# ATSAM4LC4C device description
Architecture: CORTEX-M4; Family: SAM4; Series: SAM4L
Registers are 32-bit, read-write, reset 0x0 unless marked. A register's access mark holds for its fields unless they carry their own. Offsets are from the block's base; [hi:lo] are bit positions; lines under a group give offsets from that group; {n}, {i} and the like mark numbered series.

## GPIO — General-Purpose Input/Output Controller
Instances: GPIO 0x400E1000
{0x0+0x200*i} port[{i}] (i=0..2) group
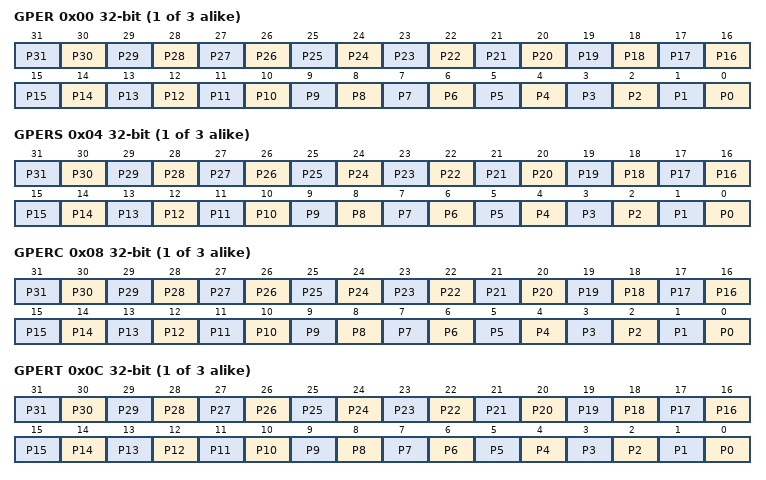
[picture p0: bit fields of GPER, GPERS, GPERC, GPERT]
  0x00 GPER reset not defined — GPIO Enable Register
    [n] P{n} (n=0..31) — GPIO Enable
  0x04 GPERS wo reset not defined (atomic set of GPER) — GPIO Enable Register - Set
    [n] P{n} (n=0..31) — GPIO Enable
  0x08 GPERC wo reset not defined (atomic clear of GPER) — GPIO Enable Register - Clear
    [n] P{n} (n=0..31) — GPIO Enable
  0x0C GPERT wo reset not defined (atomic toggle of GPER) — GPIO Enable Register - Toggle
    [n] P{n} (n=0..31) — GPIO Enable
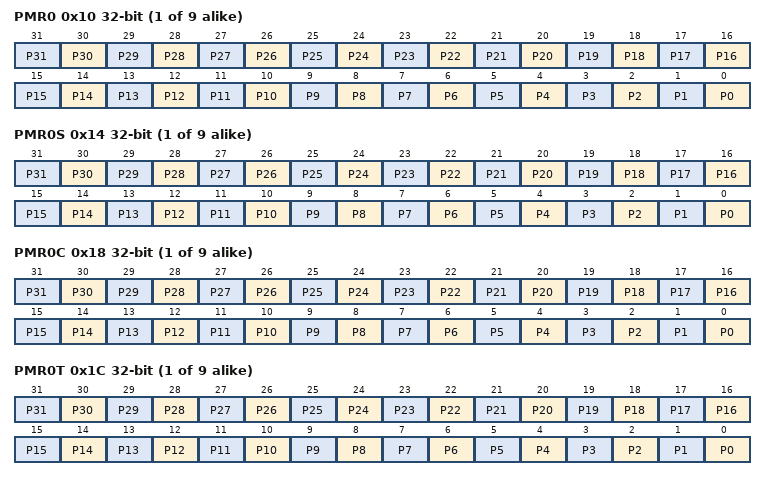
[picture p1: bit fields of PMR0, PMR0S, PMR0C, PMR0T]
  {0x10+0x10*j} PMR{j} reset not defined (j=0..2) — Peripheral Mux Register {j}
    [n] P{n} (n=0..31) — Peripheral Multiplexer Select bit {j}
  {0x14+0x10*j} PMR{j}S wo reset not defined (atomic set of PMR{j}) (j=0..2) — Peripheral Mux Register {j} - Set
    [n] P{n} (n=0..31) — Peripheral Multiplexer Select bit {j}
  {0x18+0x10*j} PMR{j}C wo reset not defined (atomic clear of PMR{j}) (j=0..2) — Peripheral Mux Register {j} - Clear
    [n] P{n} (n=0..31) — Peripheral Multiplexer Select bit {j}
  {0x1C+0x10*j} PMR{j}T wo reset not defined (atomic toggle of PMR{j}) (j=0..2) — Peripheral Mux Register {j} - Toggle
    [n] P{n} (n=0..31) — Peripheral Multiplexer Select bit {j}
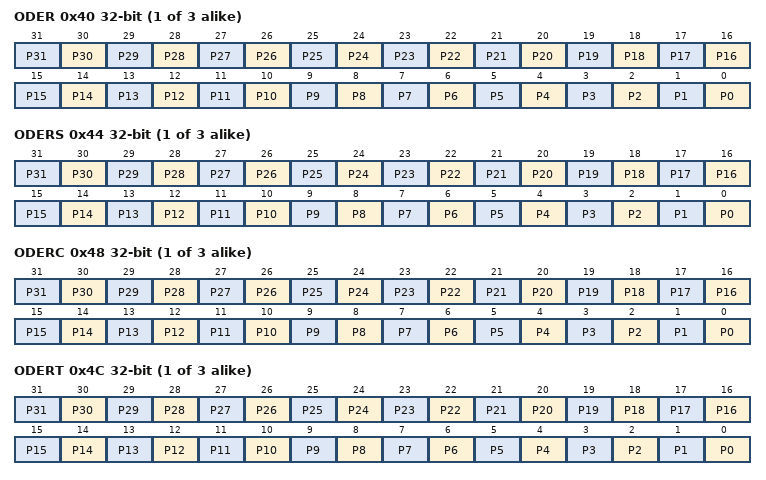
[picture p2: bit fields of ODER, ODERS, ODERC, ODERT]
  0x40 ODER reset not defined — Output Driver Enable Register
    [n] P{n} (n=0..31) — Output Driver Enable
  0x44 ODERS wo reset not defined (atomic set of ODER) — Output Driver Enable Register - Set
    [n] P{n} (n=0..31) — Output Driver Enable
  0x48 ODERC wo reset not defined (atomic clear of ODER) — Output Driver Enable Register - Clear
    [n] P{n} (n=0..31) — Output Driver Enable
  0x4C ODERT wo reset not defined (atomic toggle of ODER) — Output Driver Enable Register - Toggle
    [n] P{n} (n=0..31) — Output Driver Enable
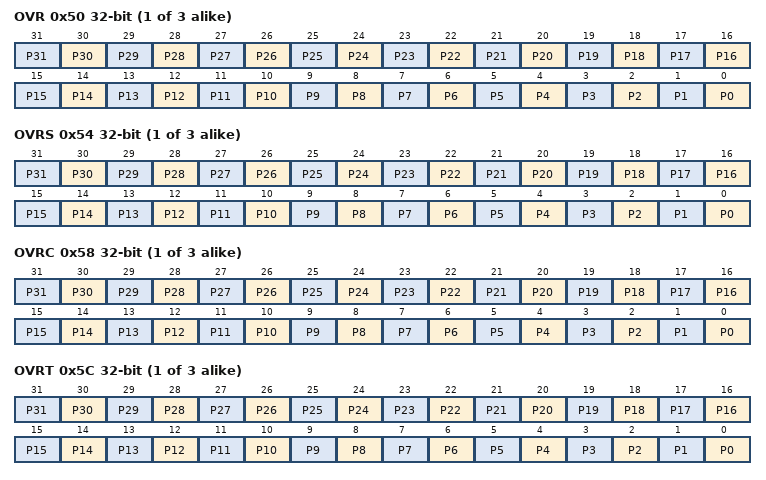
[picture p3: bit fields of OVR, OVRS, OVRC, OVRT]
  0x50 OVR reset not defined — Output Value Register
    [n] P{n} (n=0..31) — Output Value
  0x54 OVRS wo reset not defined (atomic set of OVR) — Output Value Register - Set
    [n] P{n} (n=0..31) — Output Value
  0x58 OVRC wo reset not defined (atomic clear of OVR) — Output Value Register - Clear
    [n] P{n} (n=0..31) — Output Value
  0x5C OVRT wo reset not defined (atomic toggle of OVR) — Output Value Register - Toggle
    [n] P{n} (n=0..31) — Output Value
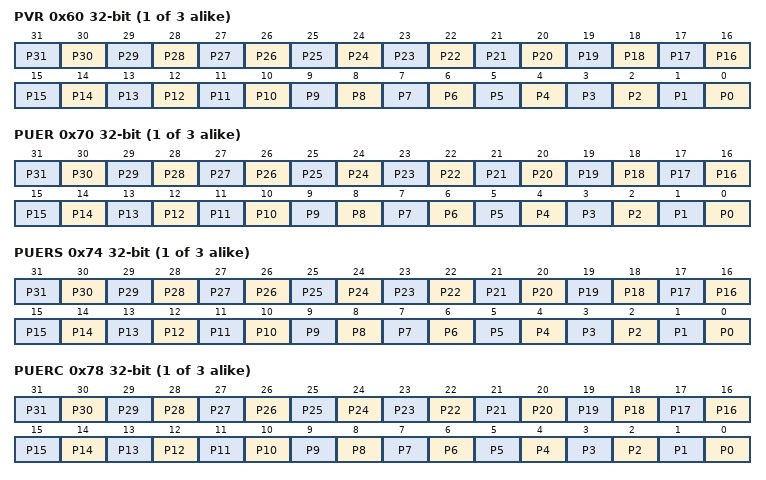
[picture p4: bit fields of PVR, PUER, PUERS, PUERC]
  0x60 PVR ro reset not defined — Pin Value Register
    [n] P{n} (n=0..31) — Pin Value
  0x70 PUER reset not defined — Pull-up Enable Register
    [n] P{n} (n=0..31) — Pull-up Enable
  0x74 PUERS wo reset not defined (atomic set of PUER) — Pull-up Enable Register - Set
    [n] P{n} (n=0..31) — Pull-up Enable
  0x78 PUERC wo reset not defined (atomic clear of PUER) — Pull-up Enable Register - Clear
    [n] P{n} (n=0..31) — Pull-up Enable
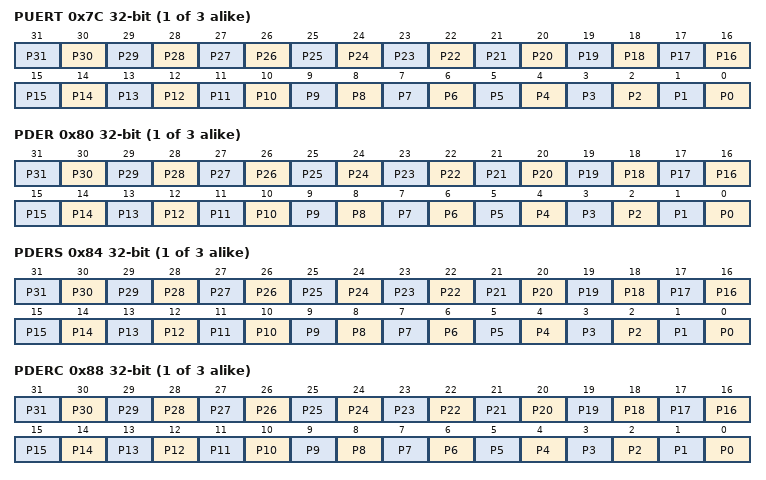
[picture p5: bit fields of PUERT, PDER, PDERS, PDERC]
  0x7C PUERT wo reset not defined (atomic toggle of PUER) — Pull-up Enable Register - Toggle
    [n] P{n} (n=0..31) — Pull-up Enable
  0x80 PDER reset not defined — Pull-down Enable Register
    [n] P{n} (n=0..31) — Pull-down Enable
  0x84 PDERS wo reset not defined (atomic set of PDER) — Pull-down Enable Register - Set
    [n] P{n} (n=0..31) — Pull-down Enable
  0x88 PDERC wo reset not defined (atomic clear of PDER) — Pull-down Enable Register - Clear
    [n] P{n} (n=0..31) — Pull-down Enable
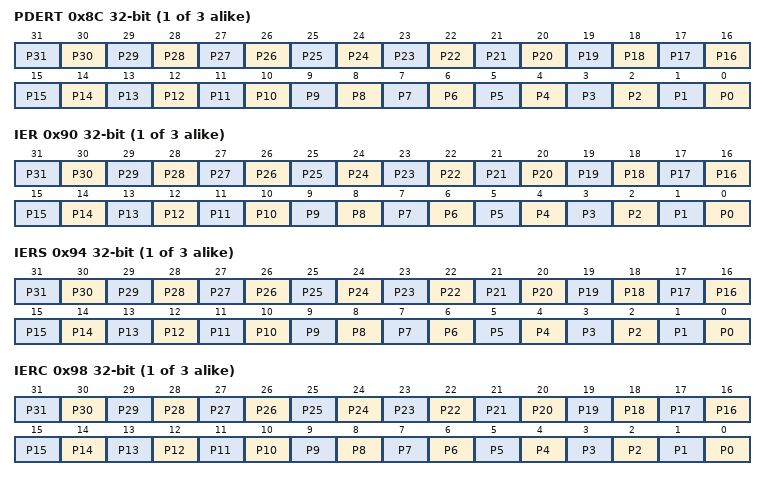
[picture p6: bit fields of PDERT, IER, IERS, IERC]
  0x8C PDERT wo reset not defined (atomic toggle of PDER) — Pull-down Enable Register - Toggle
    [n] P{n} (n=0..31) — Pull-down Enable
  0x90 IER reset not defined — Interrupt Enable Register
    [n] P{n} (n=0..31) — Interrupt Enable
  0x94 IERS wo reset not defined (atomic set of IER) — Interrupt Enable Register - Set
    [n] P{n} (n=0..31) — Interrupt Enable
  0x98 IERC wo reset not defined (atomic clear of IER) — Interrupt Enable Register - Clear
    [n] P{n} (n=0..31) — Interrupt Enable
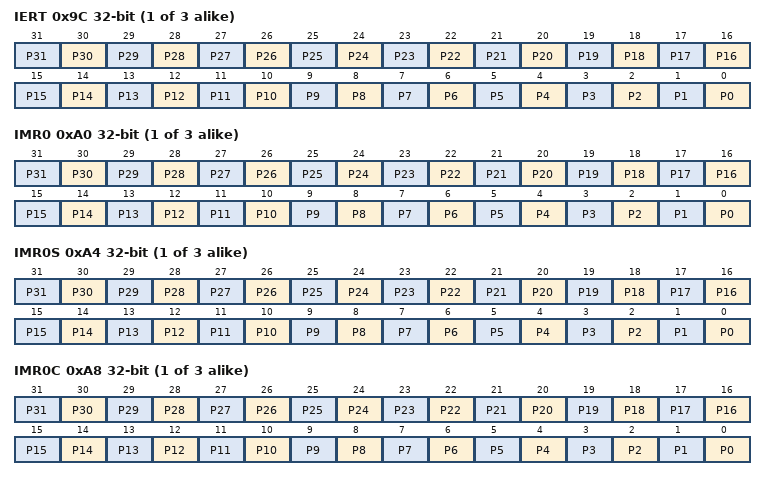
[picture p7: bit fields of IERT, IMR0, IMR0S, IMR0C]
  0x9C IERT wo reset not defined (atomic toggle of IER) — Interrupt Enable Register - Toggle
    [n] P{n} (n=0..31) — Interrupt Enable
  0xA0 IMR0 reset not defined — Interrupt Mode Register 0
    [n] P{n} (n=0..31) — Interrupt Mode Bit 0
  0xA4 IMR0S wo reset not defined (atomic set of IMR0) — Interrupt Mode Register 0 - Set
    [n] P{n} (n=0..31) — Interrupt Mode Bit 0
  0xA8 IMR0C wo reset not defined (atomic clear of IMR0) — Interrupt Mode Register 0 - Clear
    [n] P{n} (n=0..31) — Interrupt Mode Bit 0
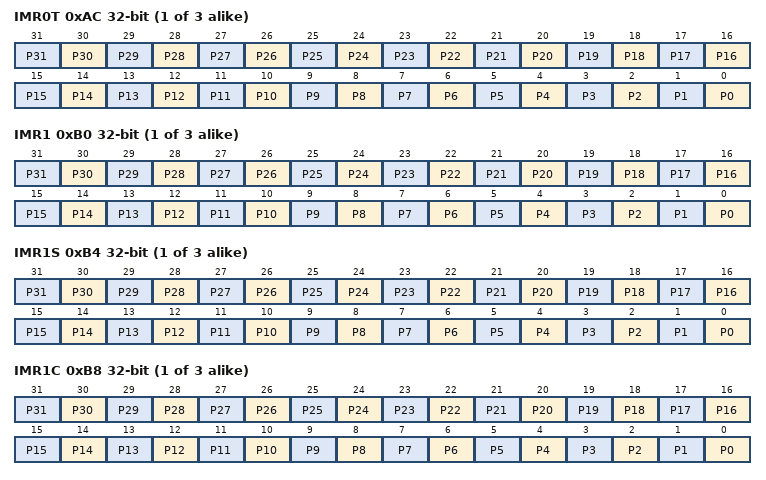
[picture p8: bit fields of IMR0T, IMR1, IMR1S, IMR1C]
  0xAC IMR0T wo reset not defined (atomic toggle of IMR0) — Interrupt Mode Register 0 - Toggle
    [n] P{n} (n=0..31) — Interrupt Mode Bit 0
  0xB0 IMR1 reset not defined — Interrupt Mode Register 1
    [n] P{n} (n=0..31) — Interrupt Mode Bit 1
  0xB4 IMR1S wo reset not defined (atomic set of IMR1) — Interrupt Mode Register 1 - Set
    [n] P{n} (n=0..31) — Interrupt Mode Bit 1
  0xB8 IMR1C wo reset not defined (atomic clear of IMR1) — Interrupt Mode Register 1 - Clear
    [n] P{n} (n=0..31) — Interrupt Mode Bit 1
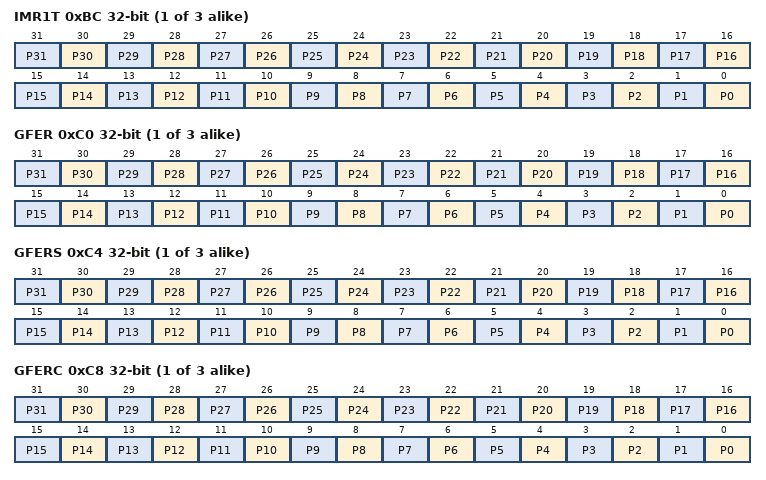
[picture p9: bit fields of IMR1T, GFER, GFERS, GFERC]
  0xBC IMR1T wo reset not defined (atomic toggle of IMR1) — Interrupt Mode Register 1 - Toggle
    [n] P{n} (n=0..31) — Interrupt Mode Bit 1
  0xC0 GFER reset not defined — Glitch Filter Enable Register
    [n] P{n} (n=0..31) — Glitch Filter Enable
  0xC4 GFERS wo reset not defined (atomic set of GFER) — Glitch Filter Enable Register - Set
    [n] P{n} (n=0..31) — Glitch Filter Enable
  0xC8 GFERC wo reset not defined (atomic clear of GFER) — Glitch Filter Enable Register - Clear
    [n] P{n} (n=0..31) — Glitch Filter Enable
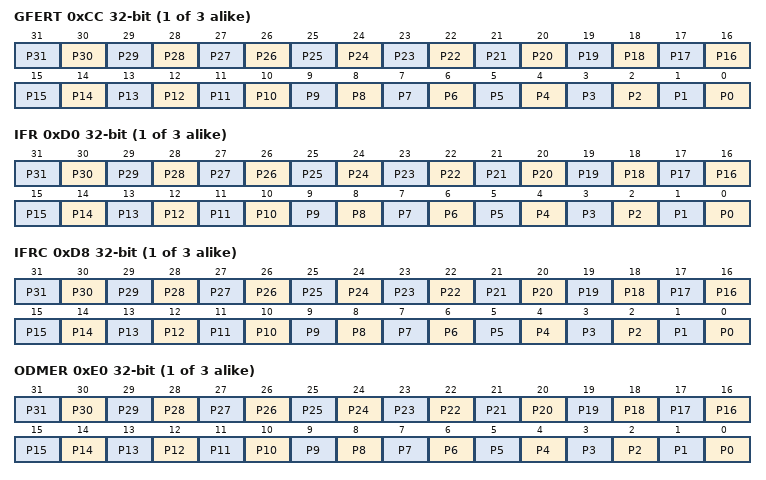
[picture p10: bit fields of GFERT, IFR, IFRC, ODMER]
  0xCC GFERT wo reset not defined (atomic toggle of GFER) — Glitch Filter Enable Register - Toggle
    [n] P{n} (n=0..31) — Glitch Filter Enable
  0xD0 IFR ro reset not defined — Interrupt Flag Register
    [n] P{n} (n=0..31) — Interrupt Flag
  0xD8 IFRC wo reset not defined (atomic clear of IFR) — Interrupt Flag Register - Clear
    [n] P{n} (n=0..31) — Interrupt Flag
  0xE0 ODMER reset not defined — Open Drain Mode Register
    [n] P{n} (n=0..31) — Open Drain Mode Enable
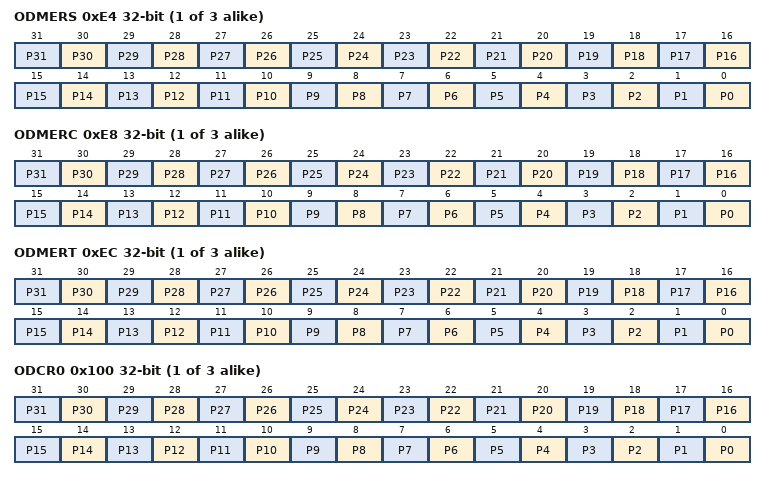
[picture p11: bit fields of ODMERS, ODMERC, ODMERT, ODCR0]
  0xE4 ODMERS wo reset not defined (atomic set of ODMER) — Open Drain Mode Register - Set
    [n] P{n} (n=0..31) — Open Drain Mode Enable
  0xE8 ODMERC wo reset not defined (atomic clear of ODMER) — Open Drain Mode Register - Clear
    [n] P{n} (n=0..31) — Open Drain Mode Enable
  0xEC ODMERT wo reset not defined (atomic toggle of ODMER) — Open Drain Mode Register - Toggle
    [n] P{n} (n=0..31) — Open Drain Mode Enable
  0x100 ODCR0 reset not defined — Output Driving Capability Register 0
    [n] P{n} (n=0..31) — Output Driving Capability Register Bit 0
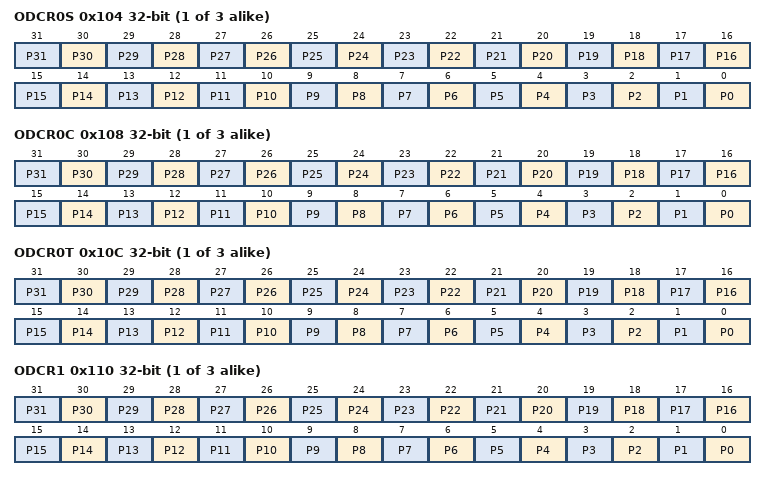
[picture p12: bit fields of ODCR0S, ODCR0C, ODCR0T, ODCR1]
  0x104 ODCR0S reset not defined (atomic set of ODCR0) — Output Driving Capability Register 0 - Set
    [n] P{n} (n=0..31) — Output Driving Capability Register Bit 0
  0x108 ODCR0C reset not defined (atomic clear of ODCR0) — Output Driving Capability Register 0 - Clear
    [n] P{n} (n=0..31) — Output Driving Capability Register Bit 0
  0x10C ODCR0T reset not defined (atomic toggle of ODCR0) — Output Driving Capability Register 0 - Toggle
    [n] P{n} (n=0..31) — Output Driving Capability Register Bit 0
  0x110 ODCR1 reset not defined — Output Driving Capability Register 1
    [n] P{n} (n=0..31) — Output Driving Capability Register Bit 1
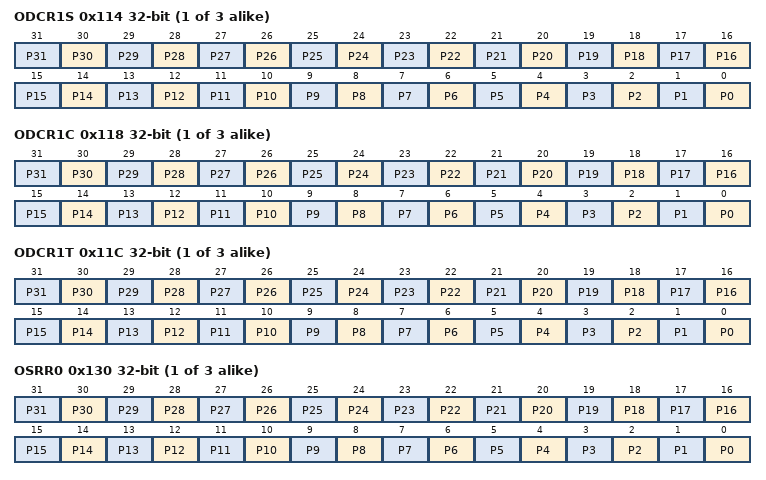
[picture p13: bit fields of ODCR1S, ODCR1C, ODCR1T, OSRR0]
  0x114 ODCR1S reset not defined (atomic set of ODCR1) — Output Driving Capability Register 1 - Set
    [n] P{n} (n=0..31) — Output Driving Capability Register Bit 1
  0x118 ODCR1C reset not defined (atomic clear of ODCR1) — Output Driving Capability Register 1 - Clear
    [n] P{n} (n=0..31) — Output Driving Capability Register Bit 1
  0x11C ODCR1T reset not defined (atomic toggle of ODCR1) — Output Driving Capability Register 1 - Toggle
    [n] P{n} (n=0..31) — Output Driving Capability Register Bit 1
  0x130 OSRR0 reset not defined — Output Slew Rate Register 0
    [n] P{n} (n=0..31) — Output Slew Rate Control Enable
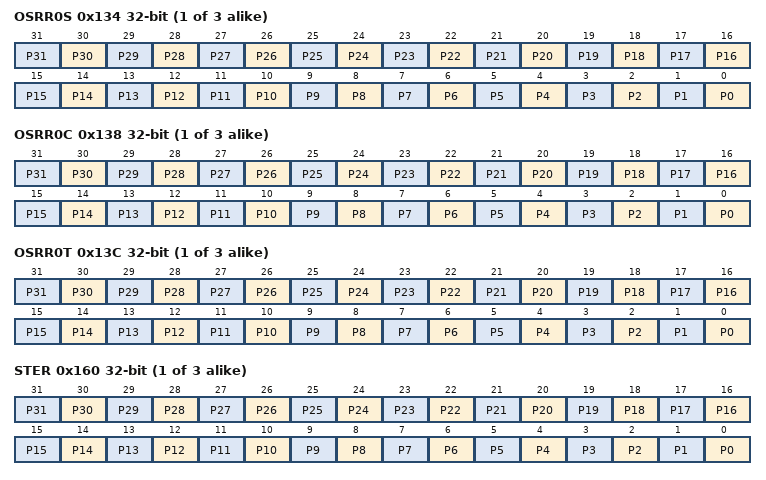
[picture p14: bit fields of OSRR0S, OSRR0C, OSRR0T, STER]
  0x134 OSRR0S reset not defined (atomic set of OSRR0) — Output Slew Rate Register 0 - Set
    [n] P{n} (n=0..31) — Output Slew Rate Control Enable
  0x138 OSRR0C reset not defined (atomic clear of OSRR0) — Output Slew Rate Register 0 - Clear
    [n] P{n} (n=0..31) — Output Slew Rate Control Enable
  0x13C OSRR0T reset not defined (atomic toggle of OSRR0) — Output Slew Rate Register 0 - Toggle
    [n] P{n} (n=0..31) — Output Slew Rate Control Enable
  0x160 STER reset not defined — Schmitt Trigger Enable Register
    [n] P{n} (n=0..31) — Schmitt Trigger Enable
  0x164 STERS reset not defined (atomic set of STER) — Schmitt Trigger Enable Register - Set
    [n] P{n} (n=0..31) — Schmitt Trigger Enable
  0x168 STERC reset not defined (atomic clear of STER) — Schmitt Trigger Enable Register - Clear
    [n] P{n} (n=0..31) — Schmitt Trigger Enable
  0x16C STERT reset not defined (atomic toggle of STER) — Schmitt Trigger Enable Register - Toggle
    [n] P{n} (n=0..31) — Schmitt Trigger Enable
  0x180 EVER reset not defined — Event Enable Register
    [n] P{n} (n=0..31) — Event Enable
  0x184 EVERS wo reset not defined (atomic set of EVER) — Event Enable Register - Set
    [n] P{n} (n=0..31) — Event Enable
  0x188 EVERC wo reset not defined (atomic clear of EVER) — Event Enable Register - Clear
    [n] P{n} (n=0..31) — Event Enable
  0x18C EVERT wo reset not defined (atomic toggle of EVER) — Event Enable Register - Toggle
    [n] P{n} (n=0..31) — Event Enable
  0x1A0 LOCK reset not defined
    [n] P{n} (n=0..31) — Lock State
  0x1A4 LOCKS wo reset not defined (atomic set of LOCK) — Lock Register - Set
    [n] P{n} (n=0..31) — Lock State
  0x1A8 LOCKC wo reset not defined (atomic clear of LOCK) — Lock Register - Clear
    [n] P{n} (n=0..31) — Lock State
  0x1AC LOCKT wo reset not defined (atomic toggle of LOCK) — Lock Register - Toggle
    [n] P{n} (n=0..31) — Lock State
  0x1E0 UNLOCK wo reset not defined
    [31:24] KEY — Unlocking Key
    [9:0] ADDR — Offset Register
  0x1E4 ASR reset not defined — Access Status Register
    [0] AR — Access Error
  0x1F8 PARAMETER ro reset not defined
  0x1FC VERSION ro reset 0x215
    [19:16] VARIANT — Variant Number
    [11:0] VERSION — Version Number

## Notices in the file
Copyright (c) 2016 Atmel Corporation,
a wholly owned subsidiary of Microchip Technology Inc.
Licensed under the Apache License, Version 2.0 (the "License");
you may not use this file except in compliance with the License.
You may obtain a copy of the Licence at
http://www.apache.org/licenses/LICENSE-2.0
Unless required by applicable law or agreed to in writing, software
distributed under the License is distributed on an "AS IS" BASIS,
WITHOUT WARRANTIES OR CONDITIONS OF ANY KIND, either express or implied.
See the License for the specific language governing permissions and
limitations under the License.
